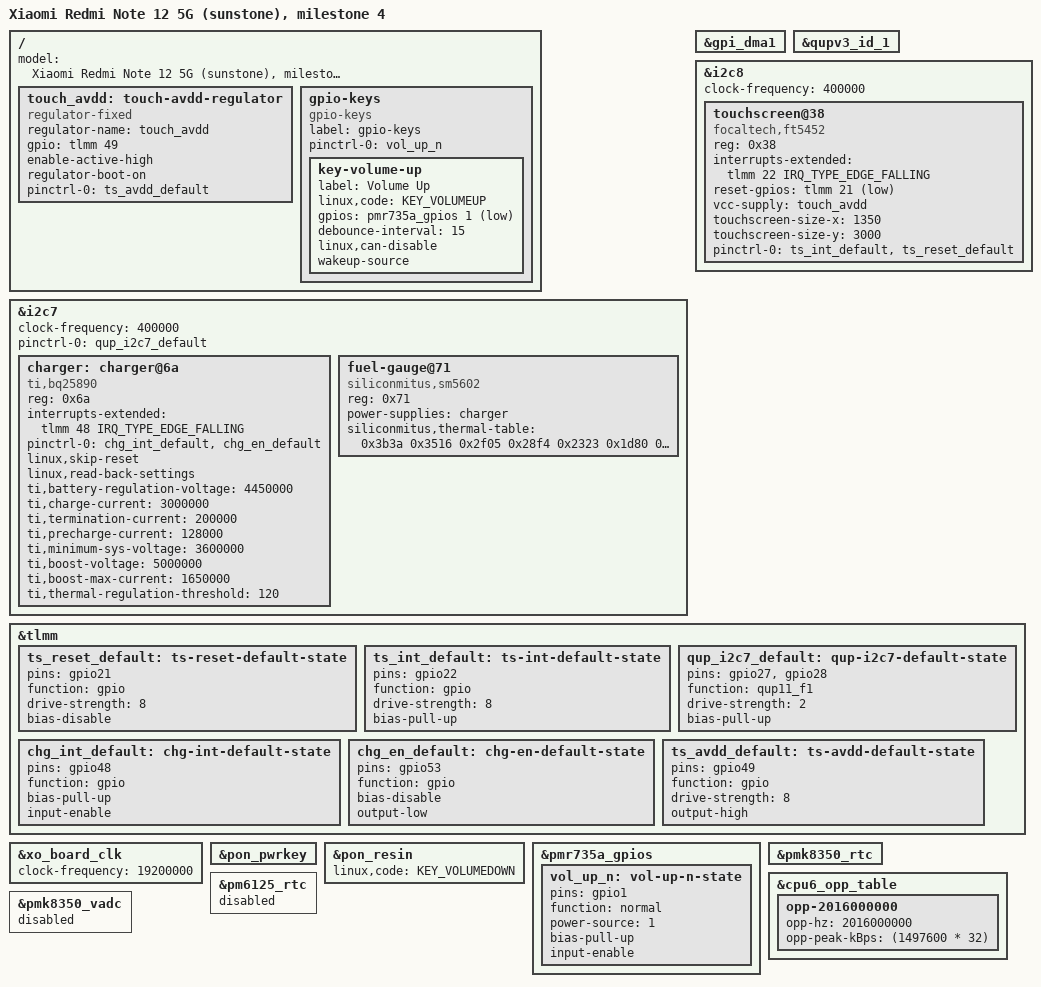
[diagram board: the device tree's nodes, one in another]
// SPDX-License-Identifier: BSD-3-Clause
/*
 * Xiaomi Redmi Note 12 5G (sunstone), SM4375 "blair": milestone 4 tree = M3 + PMICs and keys.
 *
 * The board XO frequency (left to the board by sm6375.dtsi) was missing until M4: every clock
 * rate read 0, which broke cpufreq-hw (no OPPs) and the UFS ref clock setting.
 * PMICs as on the downstream DT and Sony's pdx225: PM6125 (SID 0/1), PMK8350 on SID 6, PMR735A.
 * Keys (downstream gpio-keys and qpnp-power-on): power = PM6125 PON KPDPWR, volume down = PM6125
 * PON RESIN, volume up = PMR735A GPIO1 (active low) -- the reverse of pdx225's volume keys.
 * RTC: PMK8350 (read-only for Linux; the offset to real time is kept in userspace).
 * Touch: FocalTech FT5452 at 0x38 on i2c8 (QUP1 SE2, GPIO19/20). TZ leaves that SE in GSI mode
 * (FIFO disabled), which i2c-qcom-geni handles through GPI DMA. Reset GPIO21, IRQ GPIO22, AVDD
 * switched by GPIO49 (downstream focaltech,avdd-gpio); the IO supply stays as ABL set it.
 * Battery: on i2c7 (QUP1 SE1, GPIO27/28, FIFO mode), the SC8989X charger at 0x6a (BQ25890 register
 * map; IRQ GPIO48, charge enable GPIO53 low) and the SM5602 gauge at 0x71 (local patch 0003). The
 * charger is taken over without a reset and with the settings it already has.
 */
#define PMK8350_SID 6

#include "sm4375-xiaomi-sunstone-m3.dts"
#include "pm6125.dtsi"
#include "pmk8350.dtsi"
#include "pmr735a.dtsi"

/* the PM6125 PON is the one in use (downstream disables PMK8350's), and the labels collide */
/delete-node/ &pmk8350_pon;

/ {
	model = "Xiaomi Redmi Note 12 5G (sunstone), milestone 4";

	/* the touch controller's analog supply, switched by GPIO49; on already when ABL hands over */
	touch_avdd: touch-avdd-regulator {
		compatible = "regulator-fixed";
		regulator-name = "touch_avdd";
		gpio = <&tlmm 49 GPIO_ACTIVE_HIGH>;
		enable-active-high;
		regulator-boot-on;
		pinctrl-0 = <&ts_avdd_default>;
		pinctrl-names = "default";
	};

	gpio-keys {
		compatible = "gpio-keys";
		label = "gpio-keys";
		pinctrl-0 = <&vol_up_n>;
		pinctrl-names = "default";

		key-volume-up {
			label = "Volume Up";
			linux,code = <KEY_VOLUMEUP>;
			gpios = <&pmr735a_gpios 1 GPIO_ACTIVE_LOW>;
			debounce-interval = <15>;
			linux,can-disable;
			wakeup-source;
		};
	};
};

&i2c7 {
	clock-frequency = <400000>;
	pinctrl-0 = <&qup_i2c7_default>;
	pinctrl-names = "default";
	status = "okay";

	charger: charger@6a {
		compatible = "ti,bq25890";
		reg = <0x6a>;
		interrupts-extended = <&tlmm 48 IRQ_TYPE_EDGE_FALLING>;
		pinctrl-0 = <&chg_int_default &chg_en_default>;
		pinctrl-names = "default";

		linux,skip-reset;
		linux,read-back-settings;
		/* downstream values, used only if the read-back is not possible */
		ti,battery-regulation-voltage = <4450000>;
		ti,charge-current = <3000000>;
		ti,termination-current = <200000>;
		ti,precharge-current = <128000>;
		ti,minimum-sys-voltage = <3600000>;
		ti,boost-voltage = <5000000>;
		ti,boost-max-current = <1650000>;
		ti,thermal-regulation-threshold = <120>;
	};

	fuel-gauge@71 {
		compatible = "siliconmitus,sm5602";
		reg = <0x71>;
		power-supplies = <&charger>;
		/* battery NTC reading for -20..80 C (downstream battery0,thermal_table) */
		siliconmitus,thermal-table = <
			0x3b3a 0x3516 0x2f05 0x28f4 0x2323 0x1d80 0x1804 0x12e1 0xda7 0x8b3
			0x3d6 0xf6f2 0xf273 0xee03 0xe9d0 0xe5c7 0xe1e2 0xde2c 0xda98 0xd727
			0xd3d8 0xd0b2 0xcdac 0xcac8 0xc806 0xc55c 0xc2d0 0xc069 0xbe17 0xbbe1
			0xb9c6 0xb7c0 0xb5d3 0xb400 0xb242 0xb092 0xaefd 0xad7c 0xac06 0xaaa6
			0xa953 0xa814 0xa6de 0xa5be 0xa4a5 0xa39c 0xa2a1 0xa1b1 0xa0cb 0x9ff3
			0x9f23 0x9e59 0x9d9a 0x9ce7 0x9c3b 0x9b95 0x9af7 0x9a62 0x99d2 0x994b
			0x98cb 0x984e 0x97d6 0x9765 0x96fa 0x9693 0x9631 0x95d3 0x9579 0x9523
			0x94cf 0x9481 0x9435 0x93ec 0x93a6 0x9364 0x9325 0x92ea 0x92b1 0x927b
			0x9245 0x9212 0x91e1 0x91b2 0x9185 0x915a 0x9132 0x910b 0x90e6 0x90c2
			0x90a0 0x907e 0x905e 0x9040 0x9022 0x9006 0x8fea 0x8fd0 0x8fb7 0x8fa0
			0x8f8a>;
	};
};

&gpi_dma1 {
	status = "okay";
};

&qupv3_id_1 {
	status = "okay";
};

&i2c8 {
	clock-frequency = <400000>;
	status = "okay";

	touchscreen@38 {
		compatible = "focaltech,ft5452";
		reg = <0x38>;
		interrupts-extended = <&tlmm 22 IRQ_TYPE_EDGE_FALLING>;
		reset-gpios = <&tlmm 21 GPIO_ACTIVE_LOW>;
		vcc-supply = <&touch_avdd>;
		/* the IC reports 1.25x panel pixels (boot-11 target taps: 0.805 px per unit, both axes) */
		touchscreen-size-x = <1350>;
		touchscreen-size-y = <3000>;
		pinctrl-0 = <&ts_int_default &ts_reset_default>;
		pinctrl-names = "default";
	};
};

&tlmm {
	ts_reset_default: ts-reset-default-state {
		pins = "gpio21";
		function = "gpio";
		drive-strength = <8>;
		bias-disable;
	};

	ts_int_default: ts-int-default-state {
		pins = "gpio22";
		function = "gpio";
		drive-strength = <8>;
		bias-pull-up;
	};

	qup_i2c7_default: qup-i2c7-default-state {
		pins = "gpio27", "gpio28";
		function = "qup11_f1";
		drive-strength = <2>;
		bias-pull-up;
	};

	chg_int_default: chg-int-default-state {
		pins = "gpio48";
		function = "gpio";
		bias-pull-up;
		input-enable;
	};

	chg_en_default: chg-en-default-state {
		pins = "gpio53";
		function = "gpio";
		bias-disable;
		output-low;
	};

	ts_avdd_default: ts-avdd-default-state {
		pins = "gpio49";
		function = "gpio";
		drive-strength = <8>;
		output-high;
	};
};

&xo_board_clk {
	clock-frequency = <19200000>;
};

&pon_pwrkey {
	status = "okay";
};

&pon_resin {
	linux,code = <KEY_VOLUMEDOWN>;
	status = "okay";
};

&pmr735a_gpios {
	vol_up_n: vol-up-n-state {
		pins = "gpio1";
		function = "normal";
		power-source = <1>;
		bias-pull-up;
		input-enable;
	};
};

&pmk8350_rtc {
	status = "okay";
};

/* blair's gold cluster tops out at 2016 MHz (EPSS LUT), a step holi's table does not have */
&cpu6_opp_table {
	opp-2016000000 {
		opp-hz = /bits/ 64 <2016000000>;
		opp-peak-kBps = <(1497600 * 32)>;
	};
};

/* not used on this board: the PM6125 RTC is disabled in hardware (probe gets -EPERM), and the
 * PMK8350 ADC has no channels described yet */
&pm6125_rtc {
	status = "disabled";
};

&pmk8350_vadc {
	status = "disabled";
};
